# CY8C5888LTI_LP097 register map
File version: 0.1
CY8C58LP
Registers are 8-bit, read-write, no defined reset value unless marked. A register's access mark holds for its fields unless they carry their own. Offsets are from the block's base; lines under a group give offsets from that group; [hi:lo] are bit positions; {n}, {i} and the like mark numbered series; 'fields as' and 'values as' point back to an identical list; <NAME> marks a mode.

## Memory map
0x00000000 OneWire_TimerDelay
0x00000000 UART_1 — UART
0x40006467 OneWire_StatusReg_BUS
0x40006470 OneWire_Trigger
0x40006472 LED_Driver_Com_Driver
0x40006473 OneWire_ControlReg_SEL
0x40006476 LED_Driver_Seg_Driver_L
0x4000647D OneWire_ControlReg_DRV

## LED_Driver_Seg_Driver_L
Base 0x40006476
0x00 LED_Driver_Seg_Driver_L_CONTROL_REG

## LED_Driver_Com_Driver
Base 0x40006472
Registers as LED_Driver_Seg_Driver_L (with LED_Driver_Seg_Driver_L read as LED_Driver_Com_Driver).

## OneWire_TimerDelay
Base 0x00000000
0x4000640C OneWire_TimerDelay_COUNTER 16-bit — UDB.A0 - Current Down Counter Value
0x4000642C OneWire_TimerDelay_PERIOD 16-bit — UDB.D0 - Assigned Period
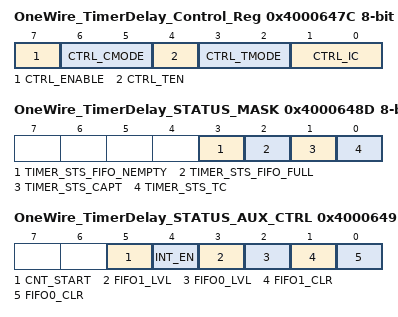
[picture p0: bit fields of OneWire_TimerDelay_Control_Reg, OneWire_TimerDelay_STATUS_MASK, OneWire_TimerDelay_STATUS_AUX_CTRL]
0x4000647C OneWire_TimerDelay_Control_Reg — UDB Control Register - Assigned Control Register Value
  [7] CTRL_ENABLE — Enable the Timer
  [6:5] CTRL_CMODE — Capture Mode
  [4] CTRL_TEN — Trigger Enable Bit
  [3:2] CTRL_TMODE — Trigger Mode
  [1:0] CTRL_IC — Interrupt Count
0x4000648D OneWire_TimerDelay_STATUS_MASK — UDB Status bits Interrupt Mask Enable Register
  [3] TIMER_STS_FIFO_NEMPTY ro — FIFO Empty status
  [2] TIMER_STS_FIFO_FULL ro — FIFO Full Status
  [1] TIMER_STS_CAPT ro — Enables the Interrupt on Capture
  [0] TIMER_STS_TC ro — Enables the Interrupt on TC
0x4000649D OneWire_TimerDelay_STATUS_AUX_CTRL — UDB Auxilliary Control Register
  [5] CNT_START — FIFO0 clear
    0=E_CNT_START0 (Disable counter); 1=E_CNT_START1 (Enable counter)
  [4] INT_EN
    0=E_INT_EN0 (Interrupt disabled); 1=E_INT_EN1 (Interrupt enabled)
  [3] FIFO1_LVL — FIFO level
    0=E_FIFO_LVL_0 (FIFO LVL: input mode: FIFO not full; output mode: FIFO not empty); 1=E_FIFO_LVL_1 (FIFO LVL: input mode: FIFO at least 1/2 empty; output mode: FIFO at least 1/2 full)
  [2] FIFO0_LVL — FIFO level
    values as FIFO1_LVL
  [1] FIFO1_CLR — FIFO1 clear
    0=E_FIFO_CLR_0 (Normal FIFO operation); 1=E_FIFO_CLR_1 (Clear FIFO state)
  [0] FIFO0_CLR — FIFO0 clear
    values as FIFO1_CLR

## OneWire_ControlReg_SEL
Base 0x40006473
Registers as LED_Driver_Seg_Driver_L (with LED_Driver_Seg_Driver_L read as OneWire_ControlReg_SEL).

## OneWire_ControlReg_DRV
Base 0x4000647D
Registers as LED_Driver_Seg_Driver_L (with LED_Driver_Seg_Driver_L read as OneWire_ControlReg_DRV).

## OneWire_StatusReg_BUS
Base 0x40006467
0x00 OneWire_StatusReg_BUS_STATUS_REG
0x20 OneWire_StatusReg_BUS_MASK_REG
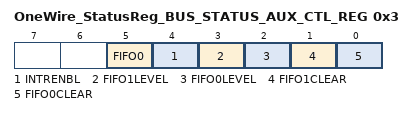
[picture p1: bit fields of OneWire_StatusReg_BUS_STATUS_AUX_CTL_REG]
0x30 OneWire_StatusReg_BUS_STATUS_AUX_CTL_REG
  [5] FIFO0 — FIFO0 clear
    1=ENABLED (Enable counter); 0=DISABLED (Disable counter)
  [4] INTRENBL — Enables or disables the Interrupt
    1=ENABLED (Interrupt enabled); 0=DISABLED (Interrupt disabled)
  [3] FIFO1LEVEL — FIFO level
    1=ENABLED (FIFO LVL: input mode: FIFO at least 1/2 empty; output mode: FIFO at least 1/2 full); 0=DISABLED (FIFO LVL: input mode: FIFO not full; output mode: FIFO not empty)
  [2] FIFO0LEVEL — FIFO level
    values as FIFO1LEVEL
  [1] FIFO1CLEAR — FIFO clear
    1=ENABLED (Clear FIFO state); 0=DISABLED (Normal FIFO operation)
  [0] FIFO0CLEAR — FIFO clear
    values as FIFO1CLEAR

## OneWire_Trigger
Base 0x40006470
Registers as LED_Driver_Seg_Driver_L (with LED_Driver_Seg_Driver_L read as OneWire_Trigger).

## UART_1 — UART
Base 0x00000000
0x40006443 TX_UART_1_TX_DATA — TX Data Register
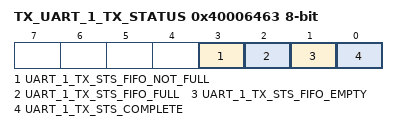
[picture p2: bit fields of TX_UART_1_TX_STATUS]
0x40006463 TX_UART_1_TX_STATUS — TX status register
  [3] UART_1_TX_STS_FIFO_NOT_FULL ro, [2] UART_1_TX_STS_FIFO_FULL ro, [1] UART_1_TX_STS_FIFO_EMPTY ro, [0] UART_1_TX_STS_COMPLETE ro
